# TLSR826X register map
File version: 0.1
Registers are 8-bit, access not given, no defined reset value unless marked. A register's access mark holds for its fields unless they carry their own. Offsets are from the block's base; [hi:lo] are bit positions.

## GPIO — Auto-generated from section 'gpio'
Base 0x00800580
0x00 GPIO_PA_IN 32-bit — Auto-generated from gpio_pa_in; aliases: GPIO_PA_SETTING1
0x01 GPIO_PA_IE — Auto-generated from gpio_pa_ie
0x02 GPIO_PA_OEN — Auto-generated from gpio_pa_oen
0x03 GPIO_PA_OUT — Auto-generated from gpio_pa_out
0x04 GPIO_PA_POL 32-bit — Auto-generated from gpio_pa_pol; aliases: GPIO_PA_SETTING2
0x05 GPIO_PA_DS — Auto-generated from gpio_pa_ds
0x06 GPIO_PA_GPIO — Auto-generated from gpio_pa_gpio
0x07 GPIO_PA_IRQ_EN — Auto-generated from gpio_pa_irq_en
0x08 GPIO_PB_IN 32-bit — Auto-generated from gpio_pb_in; aliases: GPIO_PB_SETTING1
0x09 GPIO_PB_IE — Auto-generated from gpio_pb_ie
0x0A GPIO_PB_OEN — Auto-generated from gpio_pb_oen
0x0B GPIO_PB_OUT — Auto-generated from gpio_pb_out
0x0C GPIO_PB_POL 32-bit — Auto-generated from gpio_pb_pol; aliases: GPIO_PB_SETTING2
0x0D GPIO_PB_DS — Auto-generated from gpio_pb_ds
0x0E GPIO_PB_GPIO — Auto-generated from gpio_pb_gpio
0x0F GPIO_PB_IRQ_EN — Auto-generated from gpio_pb_irq_en
0x10 GPIO_PC_IN 32-bit — Auto-generated from gpio_pc_in; aliases: GPIO_PC_SETTING1
0x11 GPIO_PC_IE — Auto-generated from gpio_pc_ie
0x12 GPIO_PC_OEN — Auto-generated from gpio_pc_oen
0x13 GPIO_PC_OUT — Auto-generated from gpio_pc_out
0x14 GPIO_PC_POL 32-bit — Auto-generated from gpio_pc_pol; aliases: GPIO_PC_SETTING2
0x15 GPIO_PC_DS — Auto-generated from gpio_pc_ds
0x16 GPIO_PC_GPIO — Auto-generated from gpio_pc_gpio
0x17 GPIO_PC_IRQ_EN — Auto-generated from gpio_pc_irq_en
0x18 GPIO_PD_IN 32-bit — Auto-generated from gpio_pd_in; aliases: GPIO_PD_SETTING1
0x19 GPIO_PD_IE — Auto-generated from gpio_pd_ie
0x1A GPIO_PD_OEN — Auto-generated from gpio_pd_oen
0x1B GPIO_PD_OUT — Auto-generated from gpio_pd_out
0x1C GPIO_PD_POL 32-bit — Auto-generated from gpio_pd_pol; aliases: GPIO_PD_SETTING2
0x1D GPIO_PD_DS — Auto-generated from gpio_pd_ds
0x1E GPIO_PD_GPIO — Auto-generated from gpio_pd_gpio
0x1F GPIO_PD_IRQ_EN — Auto-generated from gpio_pd_irq_en
0x20 GPIO_PE_IN 32-bit — Auto-generated from gpio_pe_in; aliases: GPIO_PE_SETTING1
0x21 GPIO_PE_IE — Auto-generated from gpio_pe_ie
0x22 GPIO_PE_OEN — Auto-generated from gpio_pe_oen
0x23 GPIO_PE_OUT — Auto-generated from gpio_pe_out
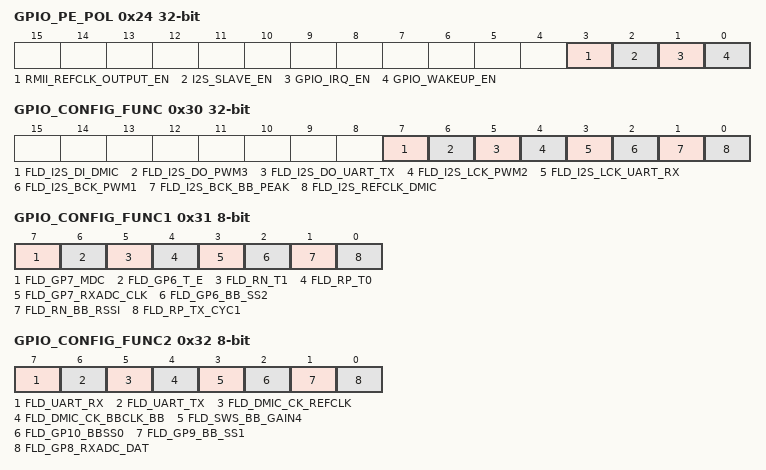
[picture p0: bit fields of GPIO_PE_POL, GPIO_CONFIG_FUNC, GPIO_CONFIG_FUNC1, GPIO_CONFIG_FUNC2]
0x24 GPIO_PE_POL 32-bit — Auto-generated from gpio_pe_pol; aliases: GPIO_CTRL, GPIO_PE_SETTING2
  [3] RMII_REFCLK_OUTPUT_EN, [2] I2S_SLAVE_EN, [1] GPIO_IRQ_EN, [0] GPIO_WAKEUP_EN
0x25 GPIO_PE_DS — Auto-generated from gpio_pe_ds
0x26 GPIO_PE_GPIO — Auto-generated from gpio_pe_gpio
0x27 GPIO_PE_IRQ_EN — Auto-generated from gpio_pe_irq_en
0x28 GPIO_PF_IN 32-bit — Auto-generated from gpio_pf_in; aliases: GPIO_PF_SETTING1
0x29 GPIO_PF_IE — Auto-generated from gpio_pf_ie
0x2A GPIO_PF_OEN — Auto-generated from gpio_pf_oen
0x2B GPIO_PF_OUT — Auto-generated from gpio_pf_out
0x2C GPIO_PF_POL 32-bit — Auto-generated from gpio_pf_pol; aliases: GPIO_PF_SETTING2
0x2D GPIO_PF_DS — Auto-generated from gpio_pf_ds
0x2E GPIO_PF_GPIO — Auto-generated from gpio_pf_gpio
0x2F GPIO_PF_IRQ_EN — Auto-generated from gpio_pf_irq_en
0x30 GPIO_CONFIG_FUNC 32-bit — Auto-generated from gpio_config_func; aliases: GPIO_CONFIG_FUNC0
  [7] FLD_I2S_DI_DMIC, [6] FLD_I2S_DO_PWM3, [5] FLD_I2S_DO_UART_TX, [4] FLD_I2S_LCK_PWM2, [3] FLD_I2S_LCK_UART_RX, [2] FLD_I2S_BCK_PWM1, [1] FLD_I2S_BCK_BB_PEAK, [0] FLD_I2S_REFCLK_DMIC
0x31 GPIO_CONFIG_FUNC1 — Auto-generated from gpio_config_func1
  [7] FLD_GP7_MDC, [6] FLD_GP6_T_E, [5] FLD_RN_T1, [4] FLD_RP_T0, [3] FLD_GP7_RXADC_CLK, [2] FLD_GP6_BB_SS2, [1] FLD_RN_BB_RSSI, [0] FLD_RP_TX_CYC1
0x32 GPIO_CONFIG_FUNC2 — Auto-generated from gpio_config_func2
  [7] FLD_UART_RX, [6] FLD_UART_TX, [5] FLD_DMIC_CK_REFCLK, [4] FLD_DMIC_CK_BBCLK_BB, [3] FLD_SWS_BB_GAIN4, [2] FLD_GP10_BBSS0, [1] FLD_GP9_BB_SS1, [0] FLD_GP8_RXADC_DAT
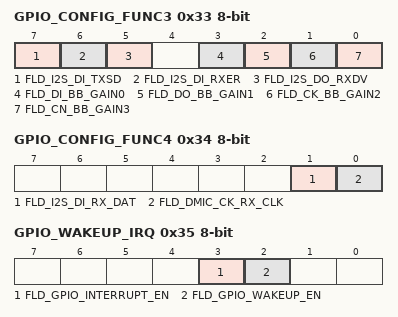
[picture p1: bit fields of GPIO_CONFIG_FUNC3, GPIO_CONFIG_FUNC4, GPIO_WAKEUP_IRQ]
0x33 GPIO_CONFIG_FUNC3 — Auto-generated from gpio_config_func3
  [7] FLD_I2S_DI_TXSD, [6] FLD_I2S_DI_RXER, [5] FLD_I2S_DO_RXDV, [3] FLD_DI_BB_GAIN0, [2] FLD_DO_BB_GAIN1, [1] FLD_CK_BB_GAIN2, [0] FLD_CN_BB_GAIN3
0x34 GPIO_CONFIG_FUNC4 — Auto-generated from gpio_config_func4
  [1] FLD_I2S_DI_RX_DAT, [0] FLD_DMIC_CK_RX_CLK
0x35 GPIO_WAKEUP_IRQ — Auto-generated from gpio_wakeup_irq
  [3] FLD_GPIO_INTERRUPT_EN, [2] FLD_GPIO_WAKEUP_EN
